# ESP32-S31 register map
Vendor: ESPRESSIF SYSTEMS (SHANGHAI) CO., LTD.; Series: ESP32 S-Series; File version: 1
CPU: RV32IMAFC r0p0, little endian, no MPU, FPU, 0 interrupt priority bits
Address unit: 32 bits
Registers are 32-bit, read-write, reset 0x0 unless marked. A register's access mark holds for its fields unless they carry their own. Offsets are from the block's base; [hi:lo] are bit positions; {n}, {i} and the like mark numbered series; 'fields as' and 'values as' point back to an identical list; <NAME> marks a mode.

## USB_OTG_HS (part 4 of 5) — USB_OTG_HS Peripheral
Base 0x20300000
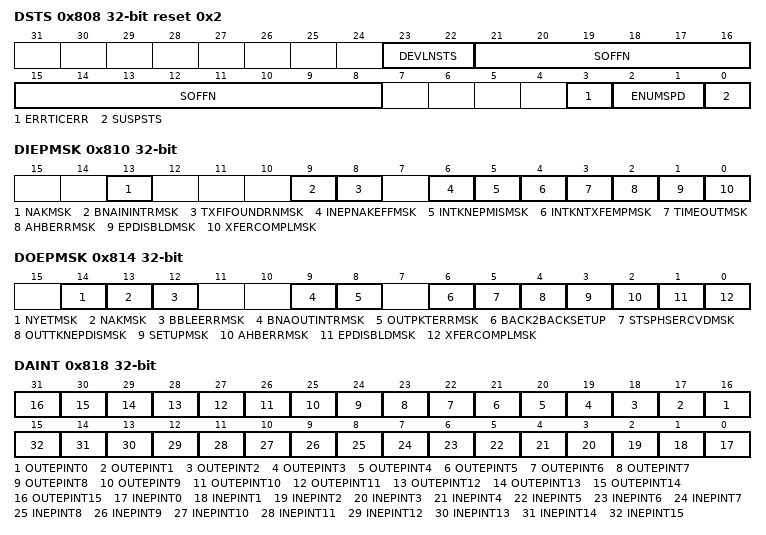
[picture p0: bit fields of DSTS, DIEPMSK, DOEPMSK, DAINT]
0x808 DSTS ro reset 0x2 — This register indicates the status of the core with respect to USB-related events. It must be read on interrupts from Device All Interrupts (DAINT) register.
  [23:22] DEVLNSTS — Device Line Status (DevLnSts) Indicates the current logic level USB data lines - DevLnSts[1]: Logic level of D+ - DevLnSts[0]: Logic level of D-
  [21:8] SOFFN — Frame or Microframe Number of the Received SOF (SOFFN) When the core is operating at high speed, this field contains a microframe number. When the core is operating at full or low speed, this field contains a Frame number. Note: This register may return a non-zero value if read immediately after power-on reset. In case the register bit reads non-zero immediately after power-on reset, it does not indicate that SOF has been received from the host. The read value of this interrupt is valid only after a valid connection between host and device is established.
  [3] ERRTICERR — Erratic Error (ErrticErr) The core sets this bit to report any erratic errors (phy_rxvalid_i/phy_rxvldh_i or phy_rxactive_i is asserted for at least 2 ms, due to PHY error) seen on the UTMI+. Due to erratic errors, the core goes into Suspended state and an interrupt is generated to the application with Early Suspend bit of the Core Interrupt register (GINTSTS.ErlySusp). If the early suspend is asserted due to an erratic error, the application must perform a PHY reset followed by a soft reset to controller.
  [2:1] ENUMSPD — Enumerated Speed (EnumSpd) Indicates the speed at which the controller has come up after speed detection through a connect or reset sequence. - 2'b00: High speed (PHY clock is running at 30 or 60 MHz) - 2'b01: Full speed (PHY clock is running at 30 or 60 MHz) - 2'b10: Low speed (PHY clock is running at 6 MHz) - 2'b11: Full speed (PHY clock is running at 48 MHz) Low speed is not supported for devices using a UTMI+ PHY.
  [0] SUSPSTS — Suspend Status (SuspSts) In Device mode, this bit is set as long as a Suspend condition is detected on the USB. The core enters the Suspend state when there is no activity on the phy_line_state_i signal for an extended period of time. The core comes out of the suspend under the following conditions : - If there is any activity on the phy_line_state_i signal, or - If the application writes to the Remote Wakeup Signaling bit in the Device Control register (DCTL.RmtWkUpSig). When the core comes out of the suspend, this bit is set to 1'b0.
0x810 DIEPMSK — This register works with each of the Device IN Endpoint Interrupt (DIEPINTn) registers for all endpoints to generate an interrupt per IN endpoint. The IN endpoint interrupt for a specific status in the DIEPINTn register can be masked by writing to the corresponding bit in this register. Status bits are masked by default.
  [13] NAKMSK — NAK interrupt Mask (NAKMsk)
  [9] BNAININTRMSK — BNA interrupt Mask (BNAInIntrMsk)
  [8] TXFIFOUNDRNMSK — Fifo Underrun Mask (TxfifoUndrnMsk)
  [6] INEPNAKEFFMSK — IN Endpoint NAK Effective Mask (INEPNakEffMsk)
  [5] INTKNEPMISMSK — IN Token received with EP Mismatch Mask (INTknEPMisMsk)
  [4] INTKNTXFEMPMSK — IN Token Received When TxFIFO Empty Mask (INTknTXFEmpMsk)
  [3] TIMEOUTMSK — Timeout Condition Mask (TimeOUTMsk) (Non-isochronous endpoints)
  [2] AHBERRMSK — AHB Error Mask (AHBErrMsk)
  [1] EPDISBLDMSK — Endpoint Disabled Interrupt Mask (EPDisbldMsk)
  [0] XFERCOMPLMSK — Transfer Completed Interrupt Mask (XferComplMsk)
0x814 DOEPMSK — This register works with each of the Device OUT Endpoint Interrupt (DOEPINTn) registers for all endpoints to generate an interrupt per OUT endpoint. The OUT endpoint interrupt for a specific status in the DOEPINTn register can be masked by writing into the corresponding bit in this register. Status bits are masked by default.
  [14] NYETMSK — NYET interrupt Mask (NYETMsk)
  [13] NAKMSK — NAK interrupt Mask (NAKMsk)
  [12] BBLEERRMSK — Babble Error interrupt Mask (BbleErrMsk)
  [9] BNAOUTINTRMSK — BNA interrupt Mask (BnaOutIntrMsk)
  [8] OUTPKTERRMSK — OUT Packet Error Mask (OutPktErrMsk)
  [6] BACK2BACKSETUP — Back-to-Back SETUP Packets Received Mask (Back2BackSETup) Applies to control OUT endpoints only.
  [5] STSPHSERCVDMSK — Status Phase Received Mask (StsPhseRcvdMsk) Applies to control OUT endpoints only.
  [4] OUTTKNEPDISMSK — OUT Token Received when Endpoint Disabled Mask (OUTTknEPdisMsk) Applies to control OUT endpoints only.
  [3] SETUPMSK — SETUP Phase Done Mask (SetUPMsk) Applies to control endpoints only.
  [2] AHBERRMSK — AHB Error (AHBErrMsk)
  [1] EPDISBLDMSK — Endpoint Disabled Interrupt Mask (EPDisbldMsk)
  [0] XFERCOMPLMSK — Transfer Completed Interrupt Mask (XferComplMsk)
0x818 DAINT ro — When a significant event occurs on an endpoint, a Device All Endpoints Interrupt register interrupts the application using the Device OUT Endpoints Interrupt bit or Device IN Endpoints Interrupt bit of the Core Interrupt register (GINTSTS.OEPInt or GINTSTS.IEPInt, respectively). This is shown in Figure 5-2. There is one interrupt bit per endpoint, up to a maximum of 16 bits for OUT endpoints and 16 bits for IN endpoints. For a bidirectional endpoint, the corresponding IN and OUT interrupt bits are used. Bits in this register are set and cleared when the application sets and clears bits in the corresponding Device Endpoint-n Interrupt register (DIEPINTn/DOEPINTn).
  [n+16] OUTEPINT{n} (n=0..15) — OUT Endpoint {n} Interrupt Bit
  [n] INEPINT{n} (n=0..15) — IN Endpoint {n} Interrupt Bit
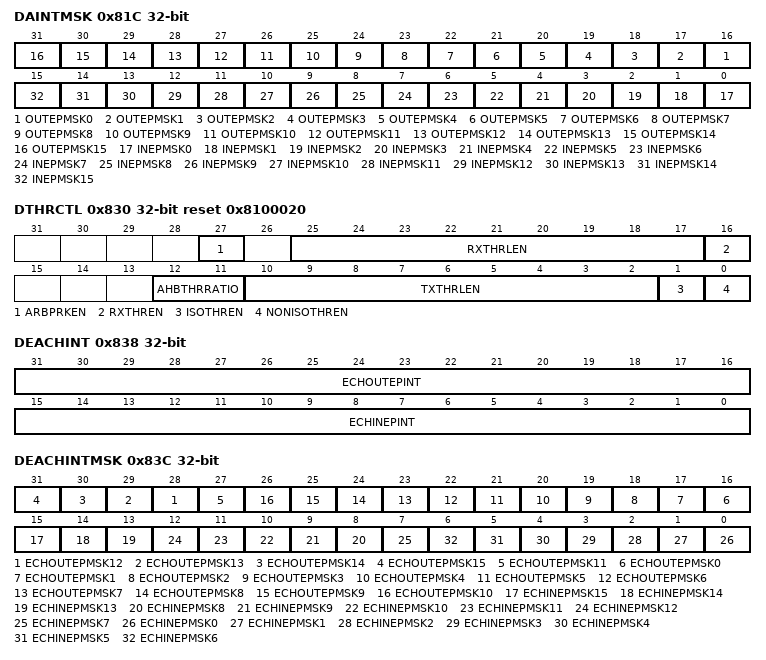
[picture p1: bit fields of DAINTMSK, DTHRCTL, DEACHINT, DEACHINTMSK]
0x81C DAINTMSK — The Device Endpoint Interrupt Mask register works with the Device Endpoint Interrupt register to interrupt the application when an event occurs on a device endpoint. However, the Device All Endpoints Interrupt (DAINT) register bit corresponding to that interrupt is still set.
  [n+16] OUTEPMSK{n} (n=0..15) — OUT Endpoint {n} Interrupt mask Bit
  [n] INEPMSK{n} (n=0..15) — IN Endpoint {n} Interrupt mask Bit
0x828 DVBUSDIS reset 0x17D7 — This register specifies the VBUS discharge time after VBUS pulsing during SRP.
  [15:0] DVBUSDIS — Device VBUS Discharge Time (DVBUSDis) Specifies the VBUS discharge time after VBUS pulsing during SRP. This value equals (VBUS discharge time in PHY clocks) / 1, 024. The value you use depends whether the PHY is operating at 30MHz (16-bit data width) or 60 MHz (8-bit data width). Depending on your VBUS load, this value can need adjustment.
0x82C DVBUSPULSE reset 0x5B8 — This register contains the VBUS pulsing time during SRP.
  [11:0] DVBUSPULSE — Device VBUS Pulsing Time (DVBUSPulse) Specifies the VBUS pulsing time during SRP. This value equals (VBUS pulsing time in PHY clocks) / 1, 024 The value you use depends whether the PHY is operating at 30MHz (16-bit data width) or 60 MHz (8-bit data width).
0x830 DTHRCTL reset 0x8100020 — This register contains the Receive and Transmit Threshold characteristics of the Device controller.
  [27] ARBPRKEN — Arbiter Parking Enable (ArbPrkEn) This bit controls internal DMA arbiter parking for IN endpoints. If thresholding is enabled and this bit is set to one, then the arbiter parks on the IN endpoint for which there is a token received on the USB. This is done to avoid getting into underrun conditions. By default, arbiter parking is enabled.
  [25:17] RXTHRLEN — Receive Threshold Length (RxThrLen) This field specifies Receive thresholding size in DWORDS. This field also specifies the amount of data received on the USB before the core can start transmitting on the AHB. The threshold length has to be at least eight DWORDS. The recommended value for ThrLen is to be the same as the programmed AHB Burst Length (GAHBCFG.HBstLen).
  [16] RXTHREN — Receive Threshold Enable (RxThrEn) When this bit is set, the core enables thresholding in the receive direction. Note: We recommends that you do not enable RxThrEn, because it may cause issues in the RxFIFO especially during error conditions such as RxError and Babble.
  [12:11] AHBTHRRATIO — AHB Threshold Ratio (AHBThrRatio) These bits define the ratio between the AHB threshold and the MAC threshold for the transmit path only. The AHB threshold always remains less than or equal to the USB threshold, because this does not increase overhead. Both the AHB and the MAC threshold must be DWORD-aligned. The application needs to program TxThrLen and the AHBThrRatio to make the AHB Threshold value DWORD aligned. If the AHB threshold value is not DWORD aligned, the core might not behave correctly. When programming the TxThrLen and AHBThrRatio, the application must ensure that the minimum AHB threshold value does not go below 8 DWORDS to meet the USB turnaround time requirements. - 2'b00: AHB threshold = MAC threshold - 2'b01: AHB threshold = MAC threshold / 2 - 2'b10: AHB threshold = MAC threshold / 4 - 2'b11: AHB threshold = MAC threshold / 8
  [10:2] TXTHRLEN — Transmit Threshold Length (TxThrLen) This field specifies Transmit thresholding size in DWORDS. This also forms the MAC threshold and specifies the amount of data in bytes to be in the corresponding endpoint transmit FIFO, before the core can start transmit on the USB. The threshold length has to be at least eight DWORDS when the value of AHBThrRatio is 2'h00. In case the AHBThrRatio is non zero the application needs to ensure that the AHB Threshold value does not go below the recommended eight DWORD. This field controls both isochronous and non-isochronous IN endpoint thresholds. The recommended value for ThrLen is to be the same as the programmed AHB Burst Length (GAHBCFG.HBstLen). Note: - When OTG_ARCHITECTURE=0, the reset value of this register field is 0. - When OTG_ARCHITECTURE=2, the reset value of this register field is 8.
  [1] ISOTHREN — ISO IN Endpoints Threshold Enable. (ISOThrEn) When this bit is Set, the core enables thresholding for isochronous IN endpoints.
  [0] NONISOTHREN — Non-ISO IN Endpoints Threshold Enable. (NonISOThrEn) When this bit is Set, the core enables thresholding for Non Isochronous IN endpoints.
0x834 DIEPEMPMSK — This register is valid only in Dedicated FIFO operation (OTG_EN_DED_TX_FIFO = 1). This register is used to control the IN endpoint FIFO empty interrupt generation (DIEPINTn.TxfEmp).
  [15:0] INEPTXFEMPMSK — IN EP Tx FIFO Empty Interrupt Mask Bits (InEpTxfEmpMsk) These bits acts as mask bits for DIEPINTn.TxFEmp interrupt, one bit per IN Endpoint: Bit 0 for IN EP 0, bit 15 for IN EP 15
0x838 DEACHINT ro — This register is available in device mode and only when parameter OTG_MULTI_PROC_INTRPT on page 121=1. There is one interrupt bit per endpoint, up to a maximum of 16 bits for OUT endpoints and 16 bits for IN endpoints. For a bidirectional endpoint, the corresponding IN and OUT interrupt bits are used. Bits in this register are set and cleared when the application sets and clears bits in the corresponding Device Endpoint-n Interrupt register (DIEPINTn/DOEPINTn). The interrupt is automatically cleared once the DOEPINTn/DIEPINTn interrupt is cleared by the application.
  [31:16] ECHOUTEPINT — Each OUT Endpoint Interrupt Bits (EchOutEPInt) One bit per OUT endpoint: Bit 16 for OUT endpoint 0, bit 31 for OUT endpoint 15
  [15:0] ECHINEPINT — Each IN Endpoint Interrupt Bits (EchInEpInt) One bit per IN Endpoint: Bit 0 for IN endpoint 0, bit 15 for endpoint 15
0x83C DEACHINTMSK — This register is available only when parameter OTG_MULTI_PROC_INTRPT=1. The Device Each Endpoint Interrupt Mask register works with the Device Each Endpoint Interrupt register to interrupt the application when an event occurs on a device endpoint. However, the Device Each Endpoints Interrupt (DEACHINT) register bit corresponding to that interrupt remains set.
  [n+16] ECHOUTEPMSK{n} (n=12..15) — OUT EP{n} Interrupt Mask Bit
  [27] ECHOUTEPMSK11 — OUT EP11 Interrupt Mask Bits
  [n+16] ECHOUTEPMSK{n} (n=0..10) — OUT EP{n} Interrupt Mask Bit
  [15] ECHINEPMSK15 — IN EP15 Interrupt Mask Bit
  [14] ECHINEPMSK14 — IN EP14 Interrupt Mask Bit
  [13] ECHINEPMSK13 — IN EP13 Interrupt Mask Bits
  [n] ECHINEPMSK{n} (n=8..12) — IN EP{n} Interrupt Mask Bit
  [7] ECHINEPMSK7 — IN EP7 Interrupt Mask Bits
  [n] ECHINEPMSK{n} (n=0..6) — IN EP{n} Interrupt Mask Bit
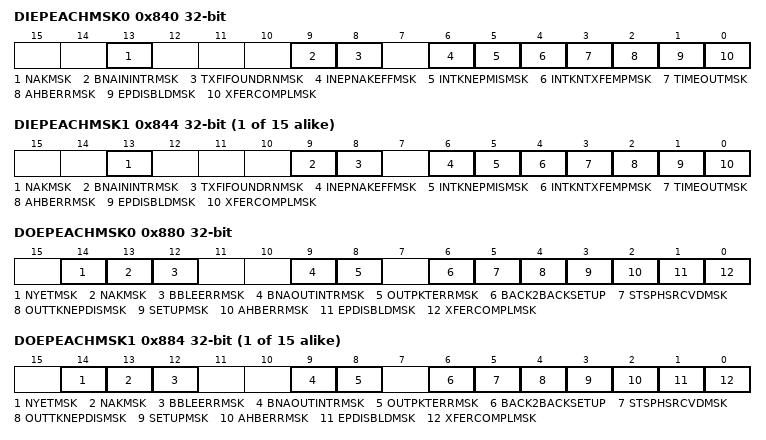
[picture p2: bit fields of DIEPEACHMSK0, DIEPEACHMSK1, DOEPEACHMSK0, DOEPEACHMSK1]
0x840 DIEPEACHMSK0 — This register is available in device mode and only when parameter OTG_MULTI_PROC_INTRPT on page 121=1. These registers are endpoint-specific mask registers for (DIEPINTn). The IN endpoint interrupt for a specific status in the DIEPINTn register can be masked by writing 0 to the corresponding bit in this register. Status bits are masked by default. - Mask interrupt: 1'b0 - Unmask interrupt: 1'b1
  fields as DIEPMSK
{0x840+4i} DIEPEACHMSK{i} (i=1..15) — This register contains the interrupts for the IN Endpoints of the Device controller. Note: This register exists for an endpoint i if the OTG_EP_DIR_i parameter is 0 or 1 for that endpoint.
  [13] NAKMSK — NAK interrupt Mask (NAKMsk)
  [9] BNAININTRMSK — BNA interrupt Mask (BNAInIntrMsk)
  [8] TXFIFOUNDRNMSK — Fifo Underrun Mask (TxfifoUndrnMsk)
  [6] INEPNAKEFFMSK — IN Endpoint NAK Effective Mask (INEPNakEffMsk)
  [5] INTKNEPMISMSK — IN Token received with EP Mismatch Mask (INTknEPMisMsk)
  [4] INTKNTXFEMPMSK — IN Token Received When TxFIFO Empty Mask(INTknTXFEmpMsk)
  [3] TIMEOUTMSK — Timeout Condition Mask (TimeOUTMsk) (Non-isochronous endpoints)
  [2] AHBERRMSK — AHB Error Mask (AHBErrMsk)
  [1] EPDISBLDMSK — Endpoint Disabled Interrupt Mask (EPDisbldMsk)
  [0] XFERCOMPLMSK — Transfer Completed Interrupt Mask (XferComplMsk)
0x880 DOEPEACHMSK0 — This register is available in device mode and only when parameter OTG_MULTI_PROC_INTRPT=1. These registers are endpoint specific mask registers for (DOEPINTn). The OUT endpoint interrupt for a specific status in the DOEPINTn register can be masked by writing 0 to the corresponding bit in this register. Status bits are masked by default.
  [14] NYETMSK — NYET interrupt Mask (NYETMsk)
  [13] NAKMSK — NAK interrupt Mask (NAKMsk)
  [12] BBLEERRMSK — Babble Error interrupt Mask (BbleErrMsk)
  [9] BNAOUTINTRMSK — BNA interrupt Mask (BnaOutIntrMsk)
  [8] OUTPKTERRMSK — OUT Packet Error Mask (OutPktErrMsk)
  [6] BACK2BACKSETUP — Back-to-Back SETUP Packets Received Mask (Back2BackSETup) Applies to control OUT endpoints only.
  [5] STSPHSRCVDMSK — Status Phase Received Mask (StsPhsRcvdMsk) Applies to control OUT endpoints only.
  [4] OUTTKNEPDISMSK — OUT Token Received when Endpoint Disabled Mask (OUTTknEPdisMsk) Applies to control OUT endpoints only.
  [3] SETUPMSK — SETUP Phase Done Mask (SetUPMsk) Applies to control endpoints only.
  [2] AHBERRMSK — AHB Error (AHBErrMsk)
  [1] EPDISBLDMSK — Endpoint Disabled Interrupt Mask (EPDisbldMsk)
  [0] XFERCOMPLMSK — Transfer Completed Interrupt Mask (XferComplMsk)
{0x880+4i} DOEPEACHMSK{i} (i=1..15) — This register contains the interrupts for the OUT Endpoints of the Device controller. Note: This register exists for an endpoint i if the OTG_EP_DIR_i parameter is 0 or 1 for that endpoint.
  fields as DOEPEACHMSK0
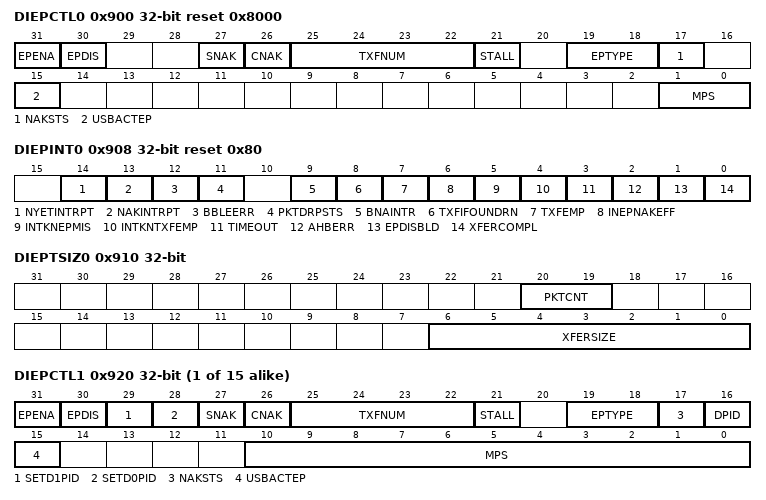
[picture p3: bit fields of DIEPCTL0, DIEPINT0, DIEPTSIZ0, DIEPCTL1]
0x900 DIEPCTL0 access per field reset 0x8000 — This register is used to control the characteristics of the IN Endpoint 0 of the Device controller.
  [31] EPENA rw — Endpoint Enable (EPEna) When Scatter/Gather DMA mode is enabled for IN endpoints, this bit indicates that the descriptor structure and data buffer with data ready to transmit is setup. When Scatter/Gather DMA mode is disabled (such as in buffer pointer based DMA mode) this bit indicates that data is ready to be transmitted on the endpoint. The core clears this bit before setting the following interrupts on this endpoint: - Endpoint Disabled - Transfer Completed
  [30] EPDIS rw — Endpoint Disable (EPDis) The application sets this bit to stop transmitting data on an endpoint, even before the transfer for that endpoint is complete. The application must wait for the Endpoint Disabled interrupt before treating the endpoint as disabled. The core clears this bit before setting the Endpoint Disabled Interrupt. The application must Set this bit only if Endpoint Enable is already set for this endpoint.
  [27] SNAK rw — Set NAK (SNAK) A write to this bit sets the NAK bit for the endpoint. Using this bit, the application can control the transmission of NAK handshakes on an endpoint. The core can also set this bit for an endpoint after a SETUP packet is received on that endpoint.
  [26] CNAK rw — Clear NAK (CNAK) A write to this bit clears the NAK bit for the endpoint.
  [25:22] TXFNUM rw — TxFIFO Number (TxFNum) - For Shared FIFO operation, this value is always set to 0, indicating that control IN endpoint 0 data is always written in the Non-Periodic Transmit FIFO. - For Dedicated FIFO operation, this value is set to the FIFO number that is assigned to IN Endpoint.
  [21] STALL rw — STALL Handshake (Stall) The application can only set this bit, and the core clears it, when a SETUP token is received for this endpoint. If a NAK bit, Global Nonperiodic IN NAK, or Global OUT NAK is set along with this bit, the STALL bit takes priority.
  [19:18] EPTYPE ro — Endpoint Type (EPType) Hardcoded to 00 for control.
  [17] NAKSTS ro — NAK Status (NAKSts) Indicates the following: - 1'b0: The core is transmitting non-NAK handshakes based on the FIFO status - 1'b1: The core is transmitting NAK handshakes on this endpoint. When this bit is set, either by the application or core, the core stops transmitting data, even If there is data available in the TxFIFO. Irrespective of this bit's setting, the core always responds to SETUP data packets with an ACK handshake.
  [15] USBACTEP ro — USB Active Endpoint (USBActEP) This bit is always SET to 1, indicating that control endpoint 0 is always active in all configurations and interfaces.
  [1:0] MPS rw — Maximum Packet Size (MPS) Applies to IN and OUT endpoints. The application must program this field with the maximum packet size for the current logical endpoint. - 2'b00: 64 bytes - 2'b01: 32 bytes - 2'b10: 16 bytes - 2'b11: 8 bytes
0x908 DIEPINT0 access per field reset 0x80 — This register indicates the status of an endpoint with respect to USB- and AHB-related events. It is shown in the Interrupt Hierarchy figure in the databook. The application must read this register when the OUT Endpoints Interrupt bit or IN Endpoints Interrupt bit of the Core Interrupt register (GINTSTS.OEPInt or GINTSTS.IEPInt, respectively) is set. Before the application can read this register, it must first read the Device All Endpoints Interrupt (DAINT) register to get the exact endpoint number for the Device Endpoint-n Interrupt register. The application must clear the appropriate bit in this register to clear the corresponding bits in the DAINT and GINTSTS registers
  [14] NYETINTRPT rw — NYET Interrupt (NYETIntrpt) The core generates this interrupt when a NYET response is transmitted for a non isochronous OUT endpoint.
  [13] NAKINTRPT rw — NAK Interrupt (NAKInterrupt) The core generates this interrupt when a NAK is transmitted or received by the device. <brIn case of isochronous IN endpoints the interrupt gets generated when a zero length packet is transmitted due to un-availability of data in the TXFifo.
  [12] BBLEERR rw — NAK Interrupt (BbleErr) The core generates this interrupt when babble is received for the endpoint.
  [11] PKTDRPSTS rw — Packet Drop Status (PktDrpSts) This bit indicates to the application that an ISOC OUT packet has been dropped. This bit does not have an associated mask bit and does not generate an interrupt. Dependency: This bit is valid in non Scatter/Gather DMA mode when periodic transfer interrupt feature is selected.
  [9] BNAINTR rw — BNA (Buffer Not Available) Interrupt (BNAIntr) This bit is valid only when Scatter/Gather DMA mode is enabled. The core generates this interrupt when the descriptor accessed is not ready for the Core to process, such as Host busy or DMA done.
  [8] TXFIFOUNDRN rw — Fifo Underrun (TxfifoUndrn) Applies to IN endpoints only. The core generates this interrupt when it detects a transmit FIFO underrun condition in threshold mode for this endpoint.
  [7] TXFEMP ro — Transmit FIFO Empty (TxFEmp) This bit is valid only for IN Endpoints This interrupt is asserted when the TxFIFO for this endpoint is either half or completely empty. The half or completely empty status is determined by the TxFIFO Empty Level bit in the Core AHB Configuration register (GAHBCFG.NPTxFEmpLvl)).
  [6] INEPNAKEFF rw — IN Endpoint NAK Effective (INEPNakEff) Applies to periodic IN endpoints only. This bit can be cleared when the application clears the IN endpoint NAK by writing to DIEPCTLn.CNAK. This interrupt indicates that the core has sampled the NAK bit Set (either by the application or by the core). The interrupt indicates that the IN endpoint NAK bit Set by the application has taken effect in the core. This interrupt does not guarantee that a NAK handshake is sent on the USB. A STALL bit takes priority over a NAK bit.
  [5] INTKNEPMIS rw — IN Token Received with EP Mismatch (INTknEPMis) Applies to non-periodic IN endpoints only. Indicates that the data in the top of the non-periodic TxFIFO belongs to an endpoint other than the one for which the IN token was received. This interrupt is asserted on the endpoint for which the IN token was received.
  [4] INTKNTXFEMP rw — IN Token Received When TxFIFO is Empty (INTknTXFEmp) Applies to non-periodic IN endpoints only. Indicates that an IN token was received when the associated TxFIFO (periodic/non-periodic) was empty. This interrupt is asserted on the endpoint for which the IN token was received.
  [3] TIMEOUT rw — Timeout Condition (TimeOUT) - In shared TX FIFO mode, applies to non-isochronous IN endpoints only. - In dedicated FIFO mode, applies only to Control IN endpoints. - In Scatter/Gather DMA mode, the TimeOUT interrupt is not asserted. Indicates that the core has detected a timeout condition on the USB for the last IN token on this endpoint.
  [2] AHBERR rw — AHB Error (AHBErr) Applies to IN and OUT endpoints. This is generated only in Internal DMA mode when there is an AHB error during an AHB read/write. The application can read the corresponding endpoint DMA address register to get the error address. For details, see AHB Error Handling in the Programming Guide.
  [1] EPDISBLD rw — Endpoint Disabled Interrupt (EPDisbld) Applies to IN and OUT endpoints. This bit indicates that the endpoint is disabled per the application's request.
  [0] XFERCOMPL rw — Transfer Completed Interrupt (XferCompl) Applies to IN and OUT endpoints. - When Scatter/Gather DMA mode is enabled -- For IN endpoint this field indicates that the requested data from the descriptor is moved from external system memory to internal FIFO. -- For OUT endpoint this field indicates that the requested data from the internal FIFO is moved to external system memory. This interrupt is generated only when the corresponding endpoint descriptor is closed, and the IOC bit for the corresponding descriptor is set. - When Scatter/Gather DMA mode is disabled, this field indicates that the programmed transfer is complete on the AHB as well as on the USB, for this endpoint.
0x910 DIEPTSIZ0 — The application must modify this register before enabling endpoint 0. Once endpoint 0 is enabled using Endpoint Enable bit of the Device Control Endpoint 0 Control registers (DIEPCTL0.EPEna/DOEPCTL0.EPEna), the core modifies this register. The application can only read this register once the core has cleared the Endpoint Enable bit. Nonzero endpoints use the registers for endpoints 115. When Scatter/Gather DMA mode is enabled, this register must not be programmed by the application. If the application reads this register when Scatter/Gather DMA mode is enabled, the core returns all zeros.
  [20:19] PKTCNT — Packet Count (PktCnt) Indicates the total number of USB packets that constitute the Transfer Size amount of data for endpoint 0. - IN Endpoints : This field is decremented every time a packet (maximum size or short packet) is read from the TxFIFO. - OUT Endpoints: This field is decremented every time a packet (maximum size or short packet) is written to the RxFIFO.
  [6:0] XFERSIZE — Transfer Size (XferSize) This field contains the transfer size in bytes for the current endpoint. The transfer size (XferSize) = Sum of buffer sizes across all descriptors in the list for the endpoint. In Buffer DMA, the core only interrupts the application after it has exhausted the transfer size amount of data. The transfer size can be set to the maximum packet size of the endpoint, to be interrupted at the end of each packet. - IN Endpoints: The core decrements this field every time a packet from the external memory is written to the TxFIFO. - OUT Endpoints: The core decrements this field every time a packet is read from the RxFIFO and written to the external memory.
0x914 DIEPDMA0 — This register contains the DMA Address for the IN Endpoint 0 of the Device controller.
  [31:0] DMAADDR — DMAAddr This field holds the start address of the external memory for storing or fetching endpoint data. Note: For control endpoints, this field stores control OUT data packets as well as SETUP transaction data packets. When more than three SETUP packets are received back-to-back, the SETUP data packet in the memory is overwritten. This register is incremented on every AHB transaction. The application can give only a DWORD-aligned address. When Scatter/Gather DMA mode is not enabled, the application programs the start address value in this field. When Scatter/Gather DMA mode is enabled, this field indicates the base pointer for the descriptor list.
0x918 DTXFSTS0 ro reset 0x400 — This register contains information about the IN Endpoint Transmit FIFO of the Device controller.
  [15:0] INEPTXFSPCAVAIL — IN Endpoint TxFIFO Space Avail (INEPTxFSpcAvail) Indicates the amount of free space available in the Endpoint TxFIFO. Values are in terms of 32-bit words. - 16'h0: Endpoint TxFIFO is full - 16'h1: 1 word available - 16'h2: 2 words available - 16'hn: n words available (where 0 n 32,768) - 16'h8000: 32,768 words available - Others: Reserved In DRD configurations (OTG_MODE = 0, 1, or 2) with dynamic FIFO sizing feature enabled (OTG_DFIFO_DYNAMIC = 1), the value of this field is, - the maximum value of (OTG_TX_HNPERIO_DFIFO_DEPTH, OTG_TX_DINEP_DFIFO_DEPTH_0) during reset, and - OTG_TX_DINEP_DFIFO_DEPTH_0, immediately after reset deassertion
0x91C DIEPDMAB0 ro — This register contains the DMA Buffer Address for the IN Endpoint 0 of the Device controller.
  [31:0] DMABUFFERADDR — Holds the current buffer address.This register is updated as and when the data transfer for the corresponding end point is in progress. This register is present only in Scatter/Gather DMA mode. Otherwise this field is reserved.
{0x900+0x20*i} DIEPCTL{i} access per field (i=1..15) — This register is used to control the characteristics of Endpoint {i}. Note: This register exists for an endpoint i if the OTG_EP_DIR_i parameter is 0 or 1 for that endpoint.
  [31] EPENA rw — Endpoint Enable (EPEna) Applies to IN and OUT endpoints. - When Scatter/Gather DMA mode is enabled, -- For IN endpoints this bit indicates that the descriptor structure and data buffer with data ready to transmit is setup. -- For OUT endpoint it indicates that the descriptor structure and data buffer to receive data is setup. - When Scatter/Gather DMA mode is enabled such as for buffer-pointer based DMA mode: -- For IN endpoints, this bit indicates that data is ready to be transmitted on the endpoint. -- For OUT endpoints, this bit indicates that the application has allocated the memory to start receiving data from the USB. - The core clears this bit before setting any of the following interrupts on this endpoint: -- SETUP Phase Done -- Endpoint Disabled -- Transfer Completed Note: For control endpoints in DMA mode, this bit must be set to be able to transfer SETUP data packets in memory.
  [30] EPDIS rw — Endpoint Disable (EPDis) Applies to IN and OUT endpoints. The application sets this bit to stop transmitting/receiving data on an endpoint, even before the transfer for that endpoint is complete. The application must wait for the Endpoint Disabled interrupt before treating the endpoint as disabled. The core clears this bit before setting the Endpoint Disabled interrupt. The application must set this bit only if Endpoint Enable is already set for this endpoint.
  [29] SETD1PID rw — Set DATA1 PID (SetD1PID) - Applies to interrupt and bulk IN endpoints only. - Writing to this field sets the Endpoint Data PID (DPID) field in this register to DATA1. - This field is applicable both for scatter-gather DMA mode and non scatter-gather DMA mode. Reset: 1'b0 Set Odd (micro)frame (SetOddFr) - Applies to isochronous IN endpoints only. - Writing to this field sets the even and odd (micro)frame (EO_FrNum) field to odd (micro)frame. Reset: 1'b0
  [28] SETD0PID rw — Set DATA0 PID (SetD0PID) - Applies to interrupt/bulk IN endpoints only. - Writing to this field sets the Endpoint Data PID (DPID) field in this register to DATA0. - This field is applicable both for Scatter/Gather DMA mode and non-Scatter/Gather DMA mode. Reset: 1'b0 In non-Scatter/Gather DMA mode: Set Even (micro)frame (SetEvenFr) - Applies to isochronous IN endpoints only. - Writing to this field sets the Even/Odd (micro)frame (EO_FrNum) field to even (micro)frame. - When Scatter/Gather DMA mode is enabled, this field is reserved. The frame number in which to send data is in the transmit descriptor structure. The frame in which to receive data is updated in receive descriptor structure. Reset: 1'b0
  [27] SNAK rw — Set NAK (SNAK) A write to this bit sets the NAK bit for the endpoint. Using this bit, the application can control the transmission of NAK handshakes on an endpoint. The core can also Set this bit for an endpoint after a SETUP packet is received on that endpoint.
  [26] CNAK rw — Clear NAK (CNAK) A write to this bit clears the NAK bit for the endpoint.
  [25:22] TXFNUM rw — TxFIFO Number (TxFNum) Shared FIFO Operation non-periodic endpoints must set this bit to zero. Periodic endpoints must map this to the corresponding Periodic TxFIFO number. - 4'h0: Non-Periodic TxFIFO - Others: Specified Periodic TxFIFO.number Note: An interrupt IN endpoint can be configured as a non-periodic endpoint for applications such as mass storage. The core treats an IN endpoint as a non-periodic endpoint if the TxFNum field is set to 0. Otherwise, a separate periodic FIFO must be allocated for an interrupt IN endpoint, and the number of this FIFO must be programmed into the TxFNum field. Configuring an interrupt IN endpoint as a non-periodic endpoint saves the extra periodic FIFO area. Dedicated FIFO Operation: These bits specify the FIFO number associated with this endpoint. Each active IN endpoint must be programmed to a separate FIFO number. This field is valid only for IN endpoints.
  [21] STALL rw — STALL Handshake (Stall) Applies to non-control, non-isochronous IN and OUT endpoints only. The application sets this bit to stall all tokens from the USB host to this endpoint. If a NAK bit, Global Non-periodic IN NAK, or Global OUT NAK is set along with this bit, the STALL bit takes priority. Only the application can clear this bit, never the core. Applies to control endpoints only. The application can only set this bit, and the core clears it, when a SETUP token is received for this endpoint. If a NAK bit, Global Non-periodic IN NAK, or Global OUT NAK is set along with this bit, the STALL bit takes priority. Irrespective of this bit's setting, the core always responds to SETUP data packets with an ACK handshake.
  [19:18] EPTYPE rw — Endpoint Type (EPType) This is the transfer type supported by this logical endpoint. - 2'b00: Control - 2'b01: Isochronous - 2'b10: Bulk - 2'b11: Interrupt
  [17] NAKSTS ro — NAK Status (NAKSts) Indicates the following: - 1'b0: The core is transmitting non-NAK handshakes based on the FIFO status. - 1'b1: The core is transmitting NAK handshakes on this endpoint. When either the application or the core sets this bit: - The core stops receiving any data on an OUT endpoint, even if there is space in the RxFIFO to accommodate the incoming packet. - For non-isochronous IN endpoints: The core stops transmitting any data on an IN endpoint, even if there data is available in the TxFIFO. - For isochronous IN endpoints: The core sends out a zero-length data packet, even if there data is available in the TxFIFO. Irrespective of this bit's setting, the core always responds to SETUP data packets with an ACK handshake.
  [16] DPID ro — Endpoint Data PID (DPID) Applies to interrupt/bulk IN and OUT endpoints only. Contains the PID of the packet to be received or transmitted on this endpoint. The application must program the PID of the first packet to be received or transmitted on this endpoint, after the endpoint is activated. The applications use the SetD1PID and SetD0PID fields of this register to program either DATA0 or DATA1 PID. - 1'b0: DATA0 - 1'b1: DATA1 This field is applicable both for Scatter/Gather DMA mode and non-Scatter/Gather DMA mode. Even/Odd (Micro)Frame (EO_FrNum) In non-Scatter/Gather DMA mode: Applies to isochronous IN and OUT endpoints only. Indicates the (micro)frame number in which the core transmits/receives isochronous data for this endpoint. The application must program the even/odd (micro)frame number in which it intends to transmit/receive isochronous data for this endpoint using the SetEvnFr and SetOddFr fields in this register. - 1'b0: Even (micro)frame - 1'b1: Odd (micro)frame When Scatter/Gather DMA mode is enabled, this field is reserved. The frame number in which to send data is provided in the transmit descriptor structure. The frame in which data is received is updated in receive descriptor structure.
  [15] USBACTEP rw — USB Active Endpoint (USBActEP) Indicates whether this endpoint is active in the current configuration and interface. The core clears this bit for all endpoints (other than EP 0) after detecting a USB reset. After receiving the SetConfiguration and SetInterface commands, the application must program endpoint registers accordingly and set this bit.
  [10:0] MPS rw — Maximum Packet Size (MPS) The application must program this field with the maximum packet size for the current logical endpoint. This value is in bytes.
